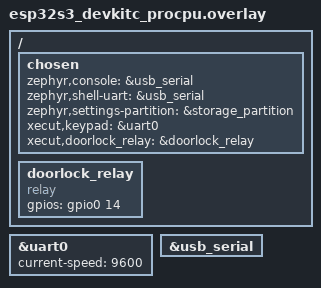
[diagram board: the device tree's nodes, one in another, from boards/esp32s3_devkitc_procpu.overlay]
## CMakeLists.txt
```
cmake_minimum_required(VERSION 3.5)

include($ENV{IDF_PATH}/tools/cmake/project.cmake)
project(xecut-lock)
```

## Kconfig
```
menu "Xecut Lock"

config REAL_RELAY
    bool "Enable relay control over GPIO"
    default n
    help
      This setting turns on the code to control the relay.
      If it is off, the app will only write a log message for each action,
      and the relay will not be used.

endmenu

source "$ZEPHYR_BASE/Kconfig"
```

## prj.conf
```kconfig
CONFIG_MAIN_STACK_SIZE=4096
CONFIG_SYSTEM_WORKQUEUE_STACK_SIZE=4096

CONFIG_ASSERT=y

CONFIG_DEBUG_THREAD_INFO=y
CONFIG_INIT_STACKS=y
CONFIG_STACK_CANARIES=y

CONFIG_WIFI=y

CONFIG_NETWORKING=y
CONFIG_NET_LOG=y
CONFIG_NET_IPV4=y
CONFIG_NET_IPV6=y
CONFIG_NET_TCP=y
CONFIG_NET_SOCKETS=y
CONFIG_NET_L2_ETHERNET=y

CONFIG_NET_DHCPV4=y
CONFIG_DNS_RESOLVER=y

# SNTP
CONFIG_SNTP=y

# MQTT
CONFIG_MQTT_LIB=y

# OTP
CONFIG_TIMING_FUNCTIONS=y
CONFIG_MBEDTLS_SHA1=y
CONFIG_MBEDTLS_PKCS5_C=y

# KEYPAD
CONFIG_SERIAL=y
CONFIG_UART_INTERRUPT_DRIVEN=y

# POSIX (for SNTP client and other clients)
CONFIG_POSIX_API=y

# ESP32 specific
CONFIG_ESP32_WIFI_STA_AUTO_DHCPV4=y

CONFIG_ESP_WIFI_HEAP_SYSTEM=y
CONFIG_HEAP_MEM_POOL_SIZE=51200

# FLASH
CONFIG_FLASH=y
CONFIG_FLASH_MAP=y
CONFIG_NVS=y
CONFIG_SHELL=y
CONFIG_SETTINGS=y
CONFIG_SETTINGS_NVS=y
CONFIG_SETTINGS_SHELL=y

# GPIO HOG
CONFIG_GPIO_HOGS=y
```

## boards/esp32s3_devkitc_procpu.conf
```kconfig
CONFIG_REAL_RELAY=y
```

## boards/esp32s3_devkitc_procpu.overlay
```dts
/ {
    chosen {
        zephyr,console = &usb_serial;
		zephyr,shell-uart = &usb_serial;
        zephyr,settings-partition = &storage_partition;
        xecut,keypad = &uart0;
        xecut,doorlock_relay = &doorlock_relay;
    };
    doorlock_relay: doorlock_relay {
        compatible = "relay";
        gpios = <&gpio0 14 GPIO_ACTIVE_HIGH>;
    };
};

&uart0 {
    status = "okay";
    current-speed = <9600>;
};

&usb_serial {
    status = "okay";
};
```

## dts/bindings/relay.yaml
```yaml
# Copyright (c) 2023 Libre Solar Technologies GmbH
# SPDX-License-Identifier: Apache-2.0

description: GPIO pin to switch a relay output on or off

compatible: "relay"

properties:
  gpios:
    type: phandle-array
    required: true
    description: |
      The GPIO connected to the RELAY.
```

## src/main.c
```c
#include <zephyr/kernel.h>
#include <zephyr/logging/log.h>
#include <zephyr/net/socket.h>
#include <zephyr/sys/clock.h>
#include <zephyr/timing/timing.h>
#include <zephyr/devicetree.h>
#include <zephyr/drivers/uart.h>
#include <zephyr/settings/settings.h>

#include <mbedtls/md.h>
#include <mbedtls/pkcs5.h>

#include <string.h>

#include "wifi.h"
#include "dns.h"
#include "sntp.h"
#include "otp.h"
#include "keypad.h"
#include "doorlock.h"

#include <string.h>

// #define WIFI_SSID "CGA2121_7d2gR7y"
// #define WIFI_PSK  "N4fzQqD9Tsv7rjy6bp"
#define WIFI_SSID "xecut"
#define WIFI_PSK  "themostsecurepassword"

LOG_MODULE_REGISTER(MAIN, 4);

#include <mbedtls/pkcs5.h>
#define CONFIG_KDF_KEY_NAME "kdf_secret"
#define CONFIG_KDF_KEY_MAX_SIZE 16
#define CONFIG_KDF_ROUNDS 4000
#define CONFIG_OTP_KEY_SIZE 0x30
#define CONFIG_OTP_DIGITS 6
#define CONFIG_OTP_TIMESTEP 30
extern uint8_t kdf_key[CONFIG_KDF_KEY_MAX_SIZE];
extern size_t kdf_key_size;

bool command_test(uint8_t *cmd, size_t cmd_len) {
    // printf("key_size =%d \n cmd_len= %d\ncommand=%s\n",kdf_key_size cmd_len, cmd);
    // for (int i=0;i<kdf_key_size;i++){
    //     printf("%02x",kdf_key[i]);
    // }
    // printf("\n");
    // uint8_t otp_key[CONFIG_OTP_KEY_SIZE];
    // mbedtls_pkcs5_pbkdf2_hmac_ext(MBEDTLS_MD_SHA1, cmd, cmd_len, kdf_key, kdf_key_size, CONFIG_KDF_ROUNDS, sizeof(otp_key), otp_key);
    // for (int i=0;i<sizeof(otp_key);i++){
    //     printf("%02x",otp_key[i]);
    // }
    // printf("\ndone\n");
    if (!strcmp(cmd,"TST")){
        doorlock_open();
    }

    return 1;
}

bool checkin_test(uint8_t *uid, size_t uid_len, uint8_t *code, size_t code_len) {
    printf("checkin, uid=%s code=%s\n", uid, code);
    bool ret = otp_verify_kdf(uid,uid_len,code,code_len);
    printf("checkin, ret=%d\n", ret);
    if (ret) doorlock_open();
    return 1;
}

int main(void) {
    int ret;

    ret = doorlock_init();
    if (ret) {
        LOG_WRN("doorlock_init failed: %d", ret);
    }

    ret = wifi_init(WIFI_SSID, WIFI_PSK);
    if (ret) {
        LOG_WRN("wifi_init failed: %d", ret);
    }

    wifi_init(WIFI_SSID, WIFI_PSK);

    ret = wifi_connect();
    if (ret) {
        LOG_ERR("Failed to connect to WiFi: %d", ret);
        return 0;
    }
    
    try_sync_time();

    #define UART_NODE DT_CHOSEN(xecut_keypad)
    const struct device *uart = DEVICE_DT_GET(UART_NODE);

    struct keypad *kp = k_malloc(sizeof(struct keypad));
    struct keypad_callbacks kp_callbacks = {
        .command = command_test,
        .checkin = checkin_test,
    };
    __ASSERT(kp != NULL, "cannot alloc kp");
    keypad_init(uart, kp_callbacks, kp);
    otp_init();

    return 0;
}
```

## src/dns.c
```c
#include "dns.h"

#include <zephyr/kernel.h>
#include <zephyr/logging/log.h>
#include <zephyr/net/socket.h>

LOG_MODULE_REGISTER(DNS);

int dns_query(
    const char *host,
    uint16_t port,
    int family,
    int socktype,
    struct sockaddr *addr,
	socklen_t *addrlen
) {
    int ret;

    struct addrinfo hints = {
        .ai_family = family,
        .ai_socktype = socktype,
    };

    struct addrinfo *res = NULL;

    ret = getaddrinfo(host, NULL, &hints, &res);
    if (ret) {
        LOG_ERR("getaddrinfo failed with status code %d (errno %d)", ret, errno);
        return 1;
    }

    *addr = *res->ai_addr;
    *addrlen = res->ai_addrlen;

    freeaddrinfo(res);

    net_sin(addr)->sin_port = htons(port);

    char addr_str[INET6_ADDRSTRLEN] = {0};
    inet_ntop(addr->sa_family, &net_sin(addr)->sin_addr, addr_str, sizeof(addr_str));

    return 0;
}
```

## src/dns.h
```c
#pragma once

#include <stdint.h>
#include <zephyr/net/net_ip.h>

int dns_query(
    const char *host,
    uint16_t port,
    int family,
    int socktype,
    struct sockaddr *addr,
	socklen_t *addrlen
);
```

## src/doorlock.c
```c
#include "doorlock.h"

#include <zephyr/kernel.h>
#include <zephyr/logging/log.h>
#include <zephyr/devicetree.h>
#include <zephyr/drivers/gpio.h>

LOG_MODULE_REGISTER(RELAY);

#ifdef CONFIG_REAL_RELAY
#define RELAY_NODE DT_CHOSEN(xecut_doorlock_relay)
static const struct gpio_dt_spec relay = GPIO_DT_SPEC_GET(RELAY_NODE, gpios);
#endif

int doorlock_init(void) {
#ifdef CONFIG_REAL_RELAY
    if (!gpio_is_ready_dt(&relay)) {
        return EAGAIN;
    }

   return gpio_pin_configure_dt(&relay, GPIO_OUTPUT_INACTIVE);
#else
    LOG_WRN("Real door lock is disabled");
    return 0;
#endif
}

void doorlock_open(void) {
    const unsigned int key = irq_lock();

#ifdef CONFIG_REAL_RELAY
    gpio_pin_set_dt(&relay, 1);
#else
    LOG_WRN("Simulation of opening a door lock");
#endif

    k_busy_wait(200000);

#ifdef CONFIG_REAL_RELAY
    gpio_pin_set_dt(&relay, 0);
#else
    LOG_WRN("Simulation of closing a door lock");
#endif

    irq_unlock(key);
}
```

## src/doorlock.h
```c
#pragma once

int doorlock_init(void);
void doorlock_open(void);
```

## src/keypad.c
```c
#include <stdio.h>
#include <zephyr/kernel.h>
#include <zephyr/drivers/uart.h>

#include <stdint.h>

#include "keypad.h"


#include <zephyr/logging/log.h>
LOG_MODULE_REGISTER(keypad, 4);

#define KEYPAD_MAX_BUFFER_SIZE  32

#define KEYPAD_BTN_POWER   'P'
#define KEYPAD_BTN_TBL     'T'
#define KEYPAD_BTN_MEM     'M'
#define KEYPAD_BTN_BYP     'B'
#define KEYPAD_BTN_CLEAR   'C'
#define KEYPAD_BTN_ENTER   'E'
#define KEYPAD_BTN_OFF     'O'
#define KEYPAD_BTN_STAY    'S'
#define KEYPAD_BTN_SLEEP   'L'
#define KEYPAD_BTN_ARM     'A'

#define ASSERT_STATE(state, required_state) \
    __ASSERT((state) == required_state, "Required state is " #required_state " but keypad is in state %s", keypad_state_txt(state));

static enum keypad_status keypad_handle_button(struct keypad *kp, uint8_t code);
static void keypad_reset(struct keypad *kp);
static enum keypad_status keypad_next_state(struct keypad *kp);
static enum keypad_status keypad_handle_command(struct keypad *kp);
static void keypad_save_uid(struct keypad *kp);
static enum keypad_status keypad_verify_code(struct keypad *kp);
static enum keypad_status keypad_save_digit(struct keypad *kp, uint8_t code);

static void uart_int_handler(const struct device *uart_dev, void *user_data);
#define KPD_STACK_SIZE 2048
#define KPD_PRIORITY 5


K_EVENT_DEFINE(kpd_event);
K_THREAD_STACK_DEFINE(keypad_thread_stack, KPD_STACK_SIZE);
struct k_thread my_thread_data;

k_tid_t kpd_tid=NULL;


void keypad_thread(void *user_data, void *p2, void *p3){
    struct keypad *kp = (struct keypad *)user_data;
    __ASSERT(kp != NULL, "kp can`t be NULL");
    for(;;){
        printf("kp_thread wait event \n");
        k_event_wait(&kpd_event,0x3 ,false ,K_FOREVER );
        uart_irq_rx_disable(kp->device);
        printf("kp_thread got event %d\n",kpd_event.events);
        switch (kp->state) {
            case KEYPAD_STATE_COMMAND:
                keypad_handle_command(kp);
                keypad_reset(kp);
                break;
            case KEYPAD_STATE_CODE_INPUT:
                keypad_verify_code(kp);
                keypad_reset(kp);
                break;
            default:
                break;
        }
        printf("kp_thread clr event\n");
        k_event_clear(&kpd_event,kpd_event.events );
        uart_irq_rx_enable(kp->device);

    }
}

void keypad_init(
    const struct device *uart,
    struct keypad_callbacks cb,
    struct keypad *out
) {
    __ASSERT(out != NULL, "out can`t be NULL");
    uint8_t *buffer = k_malloc(KEYPAD_MAX_BUFFER_SIZE);
    __ASSERT(buffer != NULL, "Not enough memory for keypad buffer");

    uint8_t *uid_buffer = k_malloc(KEYPAD_MAX_BUFFER_SIZE);
    __ASSERT(uid_buffer != NULL, "Not enough memory for keypad uid buffer");

    *out = (struct keypad) {
        .state = KEYPAD_STATE_RESET,
        .device = uart,
        .callbacks = cb,
        .buffer = buffer,
        .buffer_len = 0,
        .uid_buffer = uid_buffer,
        .uid_buffer_len = 0,
    };


    uart_irq_callback_user_data_set(uart, uart_int_handler, (void *)out);
    uart_irq_rx_enable(uart);
    kpd_tid = k_thread_create(&my_thread_data, keypad_thread_stack,
                        K_THREAD_STACK_SIZEOF(keypad_thread_stack),
                        keypad_thread,
                        out, NULL, NULL,
                        KPD_PRIORITY, 0, K_NO_WAIT);
}

static void uart_int_handler(const struct device *uart_dev, void *user_data)
{
    uart_irq_update(uart_dev);
    struct keypad *kp = (struct keypad *)user_data;
    __ASSERT(kp != NULL, "kp can`t be NULL");
    if (uart_irq_rx_ready(uart_dev))
    {
        uint8_t byte;
        while (!uart_poll_in(uart_dev, &byte))
        {
            enum keypad_status status = keypad_handle_button(kp, byte);
            LOG_DBG("keypad_int byte %c status %s, current state is %s\n",byte, keypad_status_txt(status), keypad_state_txt(kp->state));
        }
    }
}

enum keypad_status keypad_poll(struct keypad *kp) {
    __ASSERT(kp != NULL, "kp can`t be NULL");
    uint8_t byte;

    if (uart_poll_in(kp->device, &byte)) {
        return KEYPAD_STATUS_EMPTY_UART;
    }

    return keypad_handle_button(kp, byte);
}

static enum keypad_status keypad_handle_button(struct keypad *kp, uint8_t code) {
    __ASSERT(kp != NULL, "kp can`t be NULL");
    switch (code) {
        // Reset state
        case KEYPAD_BTN_CLEAR:
            keypad_reset(kp);
            return KEYPAD_STATUS_OK;

        // Special code
        case KEYPAD_BTN_POWER:
            if (kp->state == KEYPAD_STATE_RESET) {
                kp->state = KEYPAD_STATE_COMMAND;
                return KEYPAD_STATUS_OK;
            } else {
                return KEYPAD_STATUS_INVALID_STATE;
            }

        // Next state
        case KEYPAD_BTN_ENTER:
            return keypad_next_state(kp);

        // Some numbers
        case '1':
        case '2':
        case '3':
        case '4':
        case '5':
        case '6':
        case '7':
        case '8':
        case '9':
        case '0':
            return keypad_save_digit(kp, code);

        // Unused buttons
        case KEYPAD_BTN_TBL:
        case KEYPAD_BTN_MEM:
        case KEYPAD_BTN_BYP:
        case KEYPAD_BTN_OFF:
        case KEYPAD_BTN_STAY:
        case KEYPAD_BTN_SLEEP:
        case KEYPAD_BTN_ARM:
            if (kp->state != KEYPAD_STATE_CODE_INPUT){
                return  keypad_save_digit(kp, code);
            }
            return KEYPAD_STATUS_OK;

        // Someone connected via flipper and is trying to hack us!
        default:
            return KEYPAD_STATUS_UNKNOWN_BUTTON;
    }

    return KEYPAD_STATUS_OK;
}

static void keypad_reset(struct keypad *kp) {
    __ASSERT(kp != NULL, "kp can`t be NULL");
    kp->state = KEYPAD_STATE_RESET;

    memset(kp->buffer, 0, KEYPAD_MAX_BUFFER_SIZE);
    kp->buffer_len = 0;

    memset(kp->uid_buffer, 0, KEYPAD_MAX_BUFFER_SIZE);
    kp->uid_buffer_len = 0;
}

static enum keypad_status keypad_next_state(struct keypad *kp) {
    __ASSERT(kp != NULL, "kp can`t be NULL");
    enum keypad_status status = KEYPAD_STATUS_INVALID_STATE;

    if (kp->buffer_len == 0) {
        return status;
    }

    if (kp->state == KEYPAD_STATE_COMMAND) {
        k_event_set(&kpd_event,1 );
        // status = keypad_handle_command(kp);
        // keypad_reset(kp);
        status = KEYPAD_STATUS_OK;
    }
    else if (kp->state == KEYPAD_STATE_UID_INPUT) {
        keypad_save_uid(kp);
        kp->state = KEYPAD_STATE_CODE_INPUT;

        status = KEYPAD_STATUS_OK;
    }
    else if (kp->state == KEYPAD_STATE_CODE_INPUT) {
        k_event_set(&kpd_event,2 );
        // status = keypad_verify_code(kp);
        // keypad_reset(kp);
        status = KEYPAD_STATUS_OK;
    }

    return status;
}

static enum keypad_status keypad_handle_command(struct keypad *kp) {
    __ASSERT(kp != NULL, "kp can`t be NULL");
    ASSERT_STATE(kp->state, KEYPAD_STATE_COMMAND);

    if (!kp->callbacks.command){
        LOG_DBG("callback command is empty");
        return KEYPAD_STATUS_UNHANDLED_COMMAND;
    }
    bool result = kp->callbacks.command(
        kp->buffer,
        kp->buffer_len
    );

    return result ? KEYPAD_STATUS_OK : KEYPAD_STATUS_BAD_CODE;
}

static void keypad_save_uid(struct keypad *kp) {
    __ASSERT(kp != NULL, "kp can`t be NULL");
    ASSERT_STATE(kp->state, KEYPAD_STATE_UID_INPUT);

    memcpy(kp->uid_buffer, kp->buffer, kp->buffer_len);
    kp->uid_buffer_len = kp->buffer_len;

    memset(kp->buffer, 0, KEYPAD_MAX_BUFFER_SIZE);
    kp->buffer_len = 0;
}

static enum keypad_status keypad_verify_code(struct keypad *kp) {
    __ASSERT(kp != NULL, "kp can`t be NULL");
    ASSERT_STATE(kp->state, KEYPAD_STATE_CODE_INPUT);
    if (!kp->callbacks.checkin){
        LOG_DBG("callback checkin is empty");
        return KEYPAD_STATUS_UNHANDLED_COMMAND;
    }
    bool result = kp->callbacks.checkin(
        // UID
        kp->uid_buffer,
        kp->uid_buffer_len,
        // Code
        kp->buffer,
        kp->buffer_len
    );

    return result ? KEYPAD_STATUS_OK : KEYPAD_STATUS_BAD_CODE;
}

static enum keypad_status keypad_save_digit(struct keypad *kp, uint8_t code) {
    __ASSERT(kp != NULL, "kp can`t be NULL");
    if (kp->state == KEYPAD_STATE_RESET) {
        kp->state = KEYPAD_STATE_UID_INPUT;
    }

    if (kp->buffer_len == KEYPAD_MAX_BUFFER_SIZE) {
        return KEYPAD_STATUS_BUFFER_OVERFLOW;
    }

    kp->buffer[kp->buffer_len++] = code;

    return KEYPAD_STATUS_OK;
}

const char *keypad_state_txt(enum keypad_state state) {
    switch (state) {
        case KEYPAD_STATE_RESET:
            return "RESET";
        case KEYPAD_STATE_COMMAND:
            return "COMMAND";
        case KEYPAD_STATE_UID_INPUT:
            return "UID_INPUT";
        case KEYPAD_STATE_CODE_INPUT:
            return "CODE_INPUT";
        default:
            return "UNKNOWN";
    }
}

const char *keypad_status_txt(enum keypad_status status) {
    switch (status) {
        case KEYPAD_STATUS_OK:
            return "OK";
        case KEYPAD_STATUS_EMPTY_UART:
            return "EMPTY_UART";
        case KEYPAD_STATUS_BUFFER_OVERFLOW:
            return "BUFFER_OVERFLOW";
        case KEYPAD_STATUS_INVALID_STATE:
            return "KEYPAD_STATUS_INVALID_STATE";
        case KEYPAD_STATUS_UNHANDLED_COMMAND:
            return "UNHANDLED_COMMAND";
        case KEYPAD_STATUS_BAD_CODE:
            return "BAD_CODE";
        case KEYPAD_STATUS_UNKNOWN_BUTTON:
            return "UNKNOWN_BUTTON";
        default:
            return "UNKNOWN";
    }
}
```

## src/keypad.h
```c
#pragma once

#include <stdbool.h>

enum keypad_state {
    KEYPAD_STATE_RESET = 0,
    KEYPAD_STATE_COMMAND = 1,
    KEYPAD_STATE_UID_INPUT = 2,
    KEYPAD_STATE_CODE_INPUT = 3,
};

enum keypad_status {
    KEYPAD_STATUS_OK = 0,
    KEYPAD_STATUS_EMPTY_UART = -1,
    KEYPAD_STATUS_BUFFER_OVERFLOW = -2,
    KEYPAD_STATUS_INVALID_STATE = -3,
    KEYPAD_STATUS_UNHANDLED_COMMAND = -4,
    KEYPAD_STATUS_BAD_CODE = -5,
    KEYPAD_STATUS_UNKNOWN_BUTTON = -6,
};

struct keypad_callbacks {
    bool (*command)(uint8_t*, size_t);
    bool (*checkin)(uint8_t*, size_t, uint8_t*, size_t);
};

struct keypad {
    // Internal keypad state. See img/keypad-state.jpg
    enum keypad_state state;

    // UART
    const struct device *device;

    // Callbacks for some final states
    struct keypad_callbacks callbacks;

    // Buffer for common state
    uint8_t *buffer;
    size_t buffer_len;

    // Special buffer for UID
    uint8_t *uid_buffer;
    size_t uid_buffer_len;
};

void keypad_init(
    const struct device *uart,
    struct keypad_callbacks cb,
    struct keypad *out
);

enum keypad_status keypad_poll(struct keypad *kp);

const char *keypad_state_txt(enum keypad_state state);

const char *keypad_status_txt(enum keypad_status status);
```

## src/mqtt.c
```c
#include "mqtt.h"

#include <zephyr/kernel.h>
#include <zephyr/logging/log.h>
#include <zephyr/net/socket.h>
#include <zephyr/net/mqtt.h>
#include <zephyr/posix/poll.h>
#include <zephyr/random/random.h>

#include <stdio.h>

LOG_MODULE_REGISTER(MQTT);

#define CLIENT_ID "xecut_lock"
#define RECONNECT_DELAY  K_SECONDS(10)

enum mqtt_event {
    MQTT_EVENT_SETUP_COMPLETE,
    MQTT_EVENT_CONNECTED,
    MQTT_EVENT_CONNECTION_FAILED,
    MQTT_EVENT_DISCONNECTED,
};

static void client_setup(const char *user_name, const char *password);
static void client_broker_setup(const char *ip_addr, uint16_t port);

static void mqtt_evt_handler(
    struct mqtt_client *client,
    const struct mqtt_evt *evt
);

static struct {
    bool init;

    struct sockaddr_storage broker;
    struct mqtt_client client;
    uint8_t rx_buffer[256];
    uint8_t tx_buffer[256];

    k_tid_t tid;

    char evtq_buffer[4 * sizeof(enum mqtt_event)];
    struct k_msgq evtq;
} mqtt = {0};

K_THREAD_STACK_DEFINE(mqtt_thread_stack_area, 2048);
const int mqtt_thread_priority = 8;
struct k_thread mqtt_thread_data;

static void setup_mqtt_evtq(void);
static void start_mqtt_thread(void);
static void mqtt_thread(void *unused1, void *unused2, void *unused3);

static void mqtt_evt_handler(
    struct mqtt_client *client,
    const struct mqtt_evt *evt
) {
    const enum mqtt_evt_type mqtt_event = evt->type;

    enum mqtt_event event;

    if (mqtt_event == MQTT_EVT_CONNACK) {
        if (evt->result) {
            LOG_WRN("Failed to connect to MQTT with status code %d", evt->result);
            event = MQTT_EVENT_CONNECTION_FAILED;
        } else {
            LOG_DBG("Successfully connected to MQTT");
            event = MQTT_EVENT_CONNECTED;
        }
    }
    else if (mqtt_event == MQTT_EVT_DISCONNECT) {
        event = MQTT_EVENT_DISCONNECTED;
    }
    else if (mqtt_event == MQTT_EVT_PUBREC) {
        if (evt->result != 0) {
            LOG_WRN("MQTT PUBREC error %d", evt->result);
            return;
        }

        const struct mqtt_pubrel_param rel_param = {
            .message_id = evt->param.pubrec.message_id
        };

        int ret = mqtt_publish_qos2_release(client, &rel_param);
        if (ret != 0) {
            LOG_ERR("mqtt_publish_qos2_release failed with status code %d", ret);
        }

        return;
    }

    k_msgq_put(&mqtt.evtq, &event, K_FOREVER);
}

static int client_connect(void) {
    int ret = mqtt_connect(&mqtt.client);
    if (ret) {
        LOG_WRN("Failed to connect to MQTT broker with status code %d", ret);
        return ret;
    }

    struct pollfd pollfd = { .fd = mqtt.client.transport.tcp.sock, .events = POLLIN };
    ret = poll(&pollfd, 1, 2000);
    if (ret < 0) {
        LOG_WRN("Failed to poll MQTT broker with status code %d", ret);
        return ret;
    }

    mqtt_input(&mqtt.client);

    enum mqtt_event event;
    k_msgq_peek(&mqtt.evtq, &event);

    if (event == MQTT_EVENT_CONNECTED) {
        return 0;
    }

    mqtt_abort(&mqtt.client);
    return ENOTCONN;
}

static void client_disconnect(void) {
    int ret = mqtt_disconnect(&mqtt.client, NULL);
    if (ret) {
        mqtt_abort(&mqtt.client);
    }
}

static void client_setup(const char *user_name, const char *password) {
#define C mqtt.client

    mqtt_client_init(&C);

    C.broker = &mqtt.broker;

    C.protocol_version = MQTT_VERSION_3_1_1;
    C.transport.type = MQTT_TRANSPORT_NON_SECURE;

    C.evt_cb = mqtt_evt_handler;

    C.client_id.utf8 = (uint8_t *)CLIENT_ID;
    C.client_id.size = sizeof(CLIENT_ID) - 1;

    C.password = NULL;
    if (password != NULL) {
        if (C.password == NULL)
            C.password = k_malloc(sizeof(struct mqtt_utf8));
        C.password->utf8 = (uint8_t *)password;
        C.password->size = strlen(password);
    }

    C.user_name = NULL;
    if (user_name != NULL) {
        if (C.user_name == NULL)
            C.user_name = k_malloc(sizeof(struct mqtt_utf8));
        C.user_name->utf8 = (uint8_t *)user_name;
        C.user_name->size = strlen(user_name);
    }

    C.rx_buf = (uint8_t *)&mqtt.rx_buffer;
    C.rx_buf_size = sizeof(mqtt.rx_buffer);

    C.tx_buf = (uint8_t *)&mqtt.tx_buffer;
    C.tx_buf_size = sizeof(mqtt.tx_buffer);

#undef C
}

static void client_broker_setup(const char *ip_addr, uint16_t port) {
    struct sockaddr_in *addr = (struct sockaddr_in *)&mqtt.broker;
    addr->sin_family = AF_INET;
    addr->sin_port = htons(port);
    inet_pton(AF_INET, ip_addr, &addr->sin_addr);
}

void mqtt_init(
    const char *ip_addr,
    uint16_t port,
    const char *user_name,
    const char *password
) {
    if (mqtt.init) {
        client_disconnect();
    }

    client_broker_setup(ip_addr, port);
    client_setup(user_name, password);

    if (mqtt.init) return;

    setup_mqtt_evtq();
    start_mqtt_thread();

    LOG_WRN("Test 1");

    enum mqtt_event mqtt_event = MQTT_EVENT_SETUP_COMPLETE;
    k_msgq_put(&mqtt.evtq, &mqtt_event, K_FOREVER);

    LOG_WRN("Test 2");

    mqtt.init = true;
}

static void setup_mqtt_evtq(void) {
    k_msgq_init(
        &mqtt.evtq,
        (char*)&mqtt.evtq_buffer,
        sizeof(enum mqtt_event),
        sizeof(mqtt.evtq_buffer) / sizeof(enum mqtt_event)
    );
}

static void start_mqtt_thread(void) {
    if (mqtt.tid) return;

    mqtt.tid = k_thread_create(
        &mqtt_thread_data, mqtt_thread_stack_area,
        K_THREAD_STACK_SIZEOF(mqtt_thread_stack_area),
        mqtt_thread,
        NULL, NULL, NULL,
        mqtt_thread_priority, 0, K_NO_WAIT);
}

static void mqtt_thread(void *unused1, void *unused2, void *unused3) {
    int ret;
    enum mqtt_event event;

    for (;;) {
        mqtt_input(&mqtt.client);
        mqtt_live(&mqtt.client);

        ret = k_msgq_get(&mqtt.evtq, &event, K_NO_WAIT);
        if (ret) {
            k_yield();
            continue;
        }

        LOG_WRN("Received MQTT event: %d", event);

        switch (event) {
            case MQTT_EVENT_CONNECTED:
                LOG_INF("Successfully connected to MQTT!");
                break;

            case MQTT_EVENT_DISCONNECTED:
                LOG_WRN("MQTT is disconnected...");

            case MQTT_EVENT_CONNECTION_FAILED:
                k_sleep(RECONNECT_DELAY);

            case MQTT_EVENT_SETUP_COMPLETE:
                ret = client_connect();
                if (ret) {
                    LOG_WRN("Failed to send connection request: %d", ret);

                    const enum mqtt_event retry_event = MQTT_EVENT_CONNECTION_FAILED;
                    k_msgq_put(&mqtt.evtq, &retry_event, K_FOREVER);
                }
                break;

            default:
                break;
        }
    }
}

int mqtt_publish_msg(const char *topic, const char *payload, int qos) {
	struct mqtt_publish_param param = {0};

    param.message.topic.topic.utf8 = (uint8_t *)topic;
    param.message.topic.topic.size = strlen(topic);

	param.message.topic.qos = qos;
	param.message.payload.data = (uint8_t *)payload;
	param.message.payload.len = strlen(payload);
	param.message_id = sys_rand16_get();
	param.dup_flag = 0;
	param.retain_flag = 0;

	return mqtt_publish(&mqtt.client, &param);
}
```

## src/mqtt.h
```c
#pragma once

#include <stdint.h>

void mqtt_init(
    const char *ip_addr,
    uint16_t port,
    const char *user_name,
    const char *password
);

int mqtt_publish_msg(const char *topic, const char *payload, int qos);
```

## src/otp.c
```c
#include <byteswap.h>
#include <ctype.h>
#include <math.h>
#include <stddef.h>
#include <stdint.h>
#include <stdio.h>
#include <stdlib.h>
#include <time.h>

#include <mbedtls/md.h>
#include <mbedtls/pkcs5.h>
#include <zephyr/sys/util.h>
#include <zephyr/settings/settings.h>
#include <zephyr/logging/log.h>

LOG_MODULE_REGISTER(otp, 4);

#ifdef CONFIG_TIMING_FUNCTIONS
#include <zephyr/timing/timing.h>
#endif

#include "otp.h"

#define CONFIG_KDF_KEY_NAME "kdf_secret"
#define CONFIG_KDF_KEY_MAX_SIZE 16
#define CONFIG_KDF_ROUNDS 4000
#define CONFIG_OTP_KEY_SIZE 0x30
#define CONFIG_OTP_DIGITS 6
#define CONFIG_OTP_TIMESTEP 30

uint32_t otp_truncate(const uint8_t *digest, uint8_t digits) {
  uint64_t offset;
  uint32_t bin_code;

  offset = digest[19] & 0x0f;
  bin_code =
      (digest[offset] & 0x7fu) << 24u | (digest[offset + 1u] & 0xffu) << 16u |
      (digest[offset + 2u] & 0xffu) << 8u | (digest[offset + 3u] & 0xffu);

  return bin_code % (int)pow(10, digits);
};

uint32_t _get_otp(uint8_t key[], uint8_t key_len, uint8_t digits,
                  uint64_t step) {
  uint8_t digest[128];
#if __BYTE_ORDER__ == __ORDER_LITTLE_ENDIAN__
#ifndef bswap_64
#define bswap_64(x)                                                            \
  ((((x) & 0xff00000000000000ull) >> 56) |                                     \
   (((x) & 0x00ff000000000000ull) >> 40) |                                     \
   (((x) & 0x0000ff0000000000ull) >> 24) |                                     \
   (((x) & 0x000000ff00000000ull) >> 8) |                                      \
   (((x) & 0x00000000ff000000ull) << 8) |                                      \
   (((x) & 0x0000000000ff0000ull) << 24) |                                     \
   (((x) & 0x000000000000ff00ull) << 40) |                                     \
   (((x) & 0x00000000000000ffull) << 56))
#endif
  step = bswap_64(step);
#endif

  mbedtls_md_hmac(mbedtls_md_info_from_type(MBEDTLS_MD_SHA1), key, key_len,
                  (const unsigned char *)&step, sizeof(step), digest);
  return otp_truncate(digest, CONFIG_OTP_DIGITS);
};



uint8_t kdf_key[CONFIG_KDF_KEY_MAX_SIZE];
size_t kdf_key_size = 0;

bool otp_verify_kdf(char *uid, size_t uid_len, char *code, size_t code_len) {
  struct timespec tp;
  uint8_t otp_key[CONFIG_OTP_KEY_SIZE];
  sys_clock_gettime(SYS_CLOCK_REALTIME, &tp);
  uint32_t i_code = atoi(code);
  uint64_t step = ( tp.tv_sec / CONFIG_OTP_TIMESTEP);
  LOG_WRN("checking otp: uid=%s code=%06d\n",uid,i_code);
#ifdef CONFIG_TIMING_FUNCTIONS
  timing_start();
  timing_t start, end;
  start = timing_counter_get();
#endif
  mbedtls_pkcs5_pbkdf2_hmac_ext(MBEDTLS_MD_SHA1, uid, uid_len, kdf_key,
                                kdf_key_size, CONFIG_KDF_ROUNDS, sizeof(otp_key), otp_key);

  uint32_t otp = _get_otp(otp_key, sizeof(otp_key), CONFIG_OTP_DIGITS, step);
  bool valid = otp == i_code;
  LOG_DBG("code for %s step %llu is %06d/%06d (%d)\n", uid, step, i_code, otp, valid);
#ifdef CONFIG_TIMING_FUNCTIONS
  end = timing_counter_get();
  timing_stop();
  LOG_DBG("time: %lld\n", timing_cycles_to_ns(timing_cycles_get(&start, &end)));
#endif
  return valid;
}

int otp_init() {
  int ret;
  ret = settings_subsys_init();
  if (ret) {
    LOG_DBG("settings subsys initialization: fail (err %d)\n", ret);
    return ret;
  }
  LOG_DBG("settings subsys initialization: OK.\n");
  kdf_key_size =
      settings_load_one(CONFIG_KDF_KEY_NAME, kdf_key, sizeof(kdf_key));
    LOG_DBG("Loaded %d bytes from %s",kdf_key_size,CONFIG_KDF_KEY_NAME);
  if (kdf_key_size != CONFIG_KDF_KEY_MAX_SIZE) {
        LOG_WRN("Saved KDF key is less than configured %d/%d",kdf_key_size,CONFIG_KDF_KEY_MAX_SIZE);
    }
    return 0;
}
```

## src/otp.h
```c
#pragma once

#include <stdbool.h>
#include <stdint.h>


bool otp_verify_kdf(char *uid, size_t uid_len, char *code, size_t code_len);

int otp_init();
```

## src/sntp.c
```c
#include "sntp.h"

#include <zephyr/kernel.h>
#include <zephyr/logging/log.h>
#include <zephyr/net/socket.h>
#include <zephyr/net/socket_service.h>
#include <zephyr/net/sntp.h>
#include <zephyr/sys/clock.h>
#include <zephyr/shell/shell.h>

#include <stdint.h>

#include "dns.h"

LOG_MODULE_REGISTER(SNTP);

#define SNTP_TIMEOUT_MS  2000

static struct {
    char host[128 + 1];
    uint16_t port;
    uint32_t last_sync;
} ntp = {0};

static int set_time(struct sntp_time time) {
    struct timespec ts;
    ts.tv_sec = time.seconds;
    ts.tv_nsec = ((uint64_t)time.fraction * (1000 * 1000 * 1000)) >> 32;

    return sys_clock_settime(SYS_CLOCK_REALTIME, &ts);
}

static void try_sync_time(void) {
    int ret;

    struct sockaddr addr;
    socklen_t addrlen;
    struct sntp_ctx ctx;
    struct sntp_time time;

    ret = dns_query(ntp.host, ntp.port, AF_INET, SOCK_DGRAM, &addr, &addrlen);
    if (ret) {
        LOG_ERR("Failed to sync time: failed to resolve IP address of NTP server");
        return;
    }

    ret = sntp_init(&ctx, &addr, addrlen);
    if (ret) {
        LOG_ERR("Failed to sync time: sntp_init failed with status code %d", ret);
        goto end;
    }

    ret = sntp_query(&ctx,SNTP_TIMEOUT_MS, &time);
    if (ret) {
        LOG_ERR("Failed to sync time: sntp_query failed with status code %d", ret);
        goto end;
    }

    ret = set_time(time);
    if (ret) {
        LOG_ERR("Failed to set time: set_time failed with status code %d", ret);
        goto end;
    }

    ntp.last_sync = k_uptime_get_32();

    struct timespec tp;
    sys_clock_gettime(SYS_CLOCK_REALTIME, &tp);
    printf("Time synced successfully! Current time: %s (%lld)\n", ctime(&tp.tv_sec), tp.tv_sec);

end:
    sntp_close(&ctx);
}

void ntp_init(void) {
    // TODO: Read settings here.

    strcpy((char*)&ntp.host, "0.pool.ntp.org");
    ntp.port = 123;
}

static int cmd_server(const struct shell *sh, size_t argc, char **argv) {
    if (argc < 3) {
        shell_error(sh, "Usage: ntp server HOST PORT\n");
        return 1;
    }

    if (strlen(argv[1]) > sizeof(ntp.host) - 1) {
        shell_error(sh, "Too long host\n");
        return 1;
    }

    // TODO: Save values to settings and call ntp_init(void) again.
    strcpy((char*)&ntp.host, argv[1]);
    ntp.port = atoi(argv[2]);

    shell_print(sh, "NTP server saved!\n");

    return 0;
}

static char* format_last_sync() {
    static char buf[24];

    const uint32_t diff = (k_uptime_get_32() - ntp.last_sync) / 1000;
    const uint32_t days = diff / (24 * 3600);
    const uint16_t hours = diff % (24 * 3600) / 3600;
    const uint16_t minutes = diff % 3600 / 60;
    const uint16_t seconds = diff % 60;

    snprintf(
        (char*)&buf, sizeof(buf),
        "%dd %dh %dm %ds",
        days, hours, minutes, seconds
    );

    return (char*)&buf;
}

static int cmd_status(const struct shell *sh, size_t argc, char **argv) {
    struct timespec tp;
    sys_clock_gettime(SYS_CLOCK_REALTIME, &tp);
    shell_print(sh, "Current time: %s\n", ctime(&tp.tv_sec));

    if (ntp.host[0]) {
        shell_print(sh, "Host: %s:%d\n", ntp.host, ntp.port);
    } else {
        shell_print(sh, "Host: not set\n");
    }

    if (ntp.last_sync == 0) {
        shell_print(sh, "Time is not synchronized\n");
    } else {
        shell_print(sh, "Synced %s ago\n", format_last_sync());
    }

    return 0;
}

static int cmd_sync(const struct shell *sh, size_t argc, char **argv) {
    if (ntp.host[0] == 0) {
        shell_print(sh, "Host is not set!\n");
        return 1;
    }

    try_sync_time();
    return 0;
}

SHELL_STATIC_SUBCMD_SET_CREATE(sub_ntp,
    SHELL_CMD(server, NULL, "1", cmd_server),
    SHELL_CMD(status, NULL, "2", cmd_status),
    SHELL_CMD(sync, NULL, "3", cmd_sync),
    SHELL_SUBCMD_SET_END
);

SHELL_CMD_REGISTER(ntp, &sub_ntp, "NTP commands", NULL);
```

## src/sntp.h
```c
#pragma once

void ntp_init(void);
```
